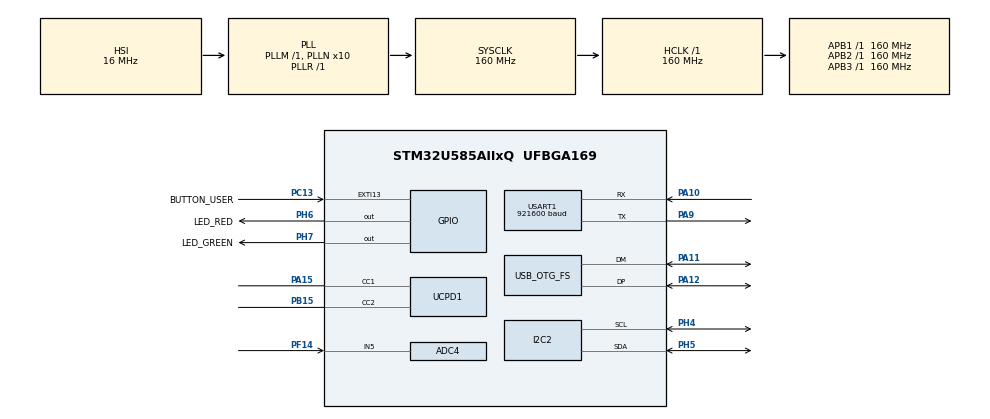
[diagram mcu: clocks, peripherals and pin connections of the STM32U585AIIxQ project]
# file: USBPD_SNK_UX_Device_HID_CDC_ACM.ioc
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ADC4.Channel-1\#ChannelRegularConversion=ADC_CHANNEL_5
ADC4.ClockPrescaler=ADC_CLOCK_ASYNC_DIV4
ADC4.ContinuousConvMode=ENABLE
ADC4.NbrOfConversion=1
ADC4.NbrOfConversionFlag=1
ADC4.OffsetNumber-1\#ChannelRegularConversion=ADC_OFFSET_NONE
ADC4.Overrun=ADC_OVR_DATA_OVERWRITTEN
ADC4.Rank-1\#ChannelRegularConversion=1
ADC4.RankArg-1\#ChannelRegularConversion=ADC4_REGULAR_RANK_1
ADC4.SamplingTime-1\#ChannelRegularConversion=ADC4_SAMPLINGTIME_COMMON_1
ADC4.SamplingTimeCommon1=ADC4_SAMPLETIME_814CYCLES_5
ADC4.SelectedChannel=ADC_CHANNEL_5
ADC4.Sequencer=FULLY_CONFIGURABLE
ADC4.TriggerFrequencyMode=ADC_TRIGGER_FREQ_HIGH
CORTEX_M33_NS.userName=CORTEX_M33
GPDMA1.DESTINC_GPDMACH5=DMA_DINC_INCREMENTED
GPDMA1.DIRECTION_GPDMACH3=DMA_MEMORY_TO_PERIPH
GPDMA1.DIRECTION_GPDMACH6=DMA_MEMORY_TO_PERIPH
GPDMA1.IPHANDLE_GPDMACH3-SIMPLEREQUEST_GPDMACH3=__NULL
GPDMA1.IPHANDLE_GPDMACH5-SIMPLEREQUEST_GPDMACH5=__NULL
GPDMA1.IPHANDLE_GPDMACH6-SIMPLEREQUEST_GPDMACH6=__NULL
GPDMA1.REQUEST_GPDMACH3=GPDMA1_REQUEST_UCPD1_TX
GPDMA1.REQUEST_GPDMACH5=GPDMA1_REQUEST_UCPD1_RX
GPDMA1.REQUEST_GPDMACH6=GPDMA1_REQUEST_USART1_TX
GPDMA1.SRCINC_GPDMACH3=DMA_SINC_INCREMENTED
GPDMA1.SRCINC_GPDMACH6=DMA_SINC_INCREMENTED
I2C2.Timing=0x30909DEC
Mcu.Family=STM32U5
Mcu.Name=STM32U585AIIxQ
Mcu.Package=UFBGA169
NVIC.EXTI13_IRQn=true\:7\:0\:true\:false\:true\:false\:true\:true\:true
NVIC.GPDMA1_Channel3_IRQn=true\:0\:0\:false\:false\:true\:true\:false\:true\:true
NVIC.GPDMA1_Channel5_IRQn=true\:0\:0\:false\:false\:true\:true\:false\:true\:true
NVIC.GPDMA1_Channel6_IRQn=true\:0\:0\:false\:false\:true\:true\:false\:true\:true
NVIC.OTG_FS_IRQn=true\:6\:0\:true\:false\:true\:false\:true\:true\:true
NVIC.PriorityGroup=NVIC_PRIORITYGROUP_4
NVIC.TIM6_IRQn=true\:15\:0\:false\:false\:true\:false\:false\:true\:true
NVIC.TimeBase=TIM6_IRQn
NVIC.TimeBaseIP=TIM6
NVIC.UCPD1_IRQn=true\:5\:0\:true\:false\:true\:false\:true\:false\:true
NVIC.USART1_IRQn=true\:4\:0\:true\:false\:true\:false\:true\:true\:true
PA10.GPIO_PuPd=GPIO_PULLUP
PA10.GPIO_Speed=GPIO_SPEED_FREQ_HIGH
PA10.Mode=Asynchronous
PA10.Signal=USART1_RX
PA11.GPIO_Speed=GPIO_SPEED_FREQ_VERY_HIGH
PA11.Mode=Device_Only
PA11.Signal=USB_OTG_FS_DM
PA12.GPIO_Speed=GPIO_SPEED_FREQ_VERY_HIGH
PA12.Mode=Device_Only
PA12.Signal=USB_OTG_FS_DP
PA15\ (JTDI).Mode=Sink_AllSignals
PA15\ (JTDI).Signal=UCPD1_CC1
PA9.GPIO_PuPd=GPIO_PULLUP
PA9.GPIO_Speed=GPIO_SPEED_FREQ_HIGH
PA9.Mode=Asynchronous
PA9.Signal=USART1_TX
PB15.Mode=Sink_AllSignals
PB15.Signal=UCPD1_CC2
PC13.GPIO_Label=BUTTON_USER
PC13.Signal=GPXTI13
PF14.Mode=IN5
PF14.Signal=ADC4_IN5
PH4.Mode=I2C
PH4.Signal=I2C2_SCL
PH5.Mode=I2C
PH5.Signal=I2C2_SDA
PH6.GPIO_Label=LED_RED
PH6.PinState=GPIO_PIN_SET
PH6.Signal=GPIO_Output
PH7.GPIO_Label=LED_GREEN
PH7.PinState=GPIO_PIN_SET
PH7.Signal=GPIO_Output
PWR.PowerMode=PWR_SMPS_SUPPLY
ProjectManager.HeapSize=0x1000
ProjectManager.StackSize=0x1000
ProjectManager.TargetToolchain=EWARM V8.50
RCC.ADCFreq_Value=16000000
RCC.AHBFreq_Value=160000000
RCC.APB1Freq_Value=160000000
RCC.APB1TimFreq_Value=160000000
RCC.APB2Freq_Value=160000000
RCC.APB2TimFreq_Value=160000000
RCC.APB3Freq_Value=160000000
RCC.CortexFreq_Value=160000000
RCC.DACCLockSelectionVirtual=RCC_DAC1CLKSOURCE_LSI
RCC.EPOD_VALUE=16000000
RCC.FLatency=FLASH_LATENCY_4
RCC.HCLKFreq_Value=160000000
RCC.HSE_VALUE=16000000
RCC.HSI48_VALUE=48000000
RCC.HSI_VALUE=16000000
RCC.LSE_VALUE=32768
RCC.LSIDIV_VALUE=32000
RCC.MSI_VALUE=4000000
RCC.PLL1R=1
RCC.PLLN=10
RCC.PLLSourceVirtual=RCC_PLLSOURCE_HSI
RCC.PWR_Regulator_Voltage_Scale=PWR_REGULATOR_VOLTAGE_SCALE1
RCC.SYSCLKFreq_VALUE=160000000
RCC.SYSCLKSource=RCC_SYSCLKSOURCE_PLLCLK
RCC.USBFreq_Value=48000000
RCC.VCOOutputFreq_Value=160000000
THREADX.AZRTOS_APP_MEM_ALLOCATION_METHOD=1
THREADX.TX_TIMER_TICKS_PER_SECOND=1000
USART1.BaudRate=921600
USART1.VirtualMode-Asynchronous=VM_ASYNC
USBPD.PE_DR_Swap_To_DFP_P0=USBPD_FALSE
USBPD.PE_DR_Swap_To_UFP_P0=USBPD_FALSE
USBPD.PE_SpecRevision_P0=USBPD_SPECIFICATION_REV3
USBPD.PORT0_SINK_PDO1=0x04019096
USBPD.USBPD_DEVICE_APP_MEM_POOL_SIZE=5000
USBPD.USBPD_PDO_FIXED_USBCOMM_P0=USBPD_PDO_FIXED_USBCOMM_SUPPORTED
USBPD.USBPD_PORT0_PDO_SNK_FIXED_SET_OP_CURRENT_0=1500
USBX.BSP.number=1
USBX.Core_System=1
USBX.MAX_POWER_IN_MILLI_AMPER=0
USBX.REG_USBX_DEVICE_CON_CK=0
USBX.USBD_CDCACM_EPINCMD_ADDR=2
USBX.USBD_CDCACM_EPIN_ADDR=1
USBX.USBD_HID_MOUSE_EPIN_ADDR=3
USBX.USBD_PID=22288
USBX.USBD_PRODUCT_STRING=STM32 HID CDC_ACM
USBX.USBD_SERIAL_NUMBER=COMP001
USBX.USBX_SYS_SIZE=10 * 1024
USBX.UX_APP_MEM_POOL_SIZE=15360
USBX.UX_DEVICE_CDC_ACM=1
USBX.UX_DEVICE_CLASS_CDC_ACM_TRANSMISSION_DISABLE=1
USBX.UX_DEVICE_CLASS_CDC_ACM_WRITE_AUTO_ZLP=1
USBX.UX_DEVICE_HID_CORE=1
USBX.UX_DEVICE_HID_MOUSE=1
USBX.UX_Device_Controller=1
USBX.UX_Device_CoreStack=1
USBX.UX_MAX_SLAVE_CLASS_DRIVER=2
USBX.UX_SLAVE_REQUEST_DATA_MAX_LENGTH=512
USBX0.BSP.STBoard=false
USBX0.BSP.api=Unknown
USBX0.BSP.instance=USB_OTG_FS
USBX0.BSP.ip=USB_OTG_FS
USBX0.BSP.mode=Device_Only
USBX0.BSP.name=USBDevice
USBX0.BSP.solution=USB_OTG_FS
USB_OTG_FS.VirtualMode=Device_Only
VP_GPDMA1_VS_GPDMACH3.Mode=SIMPLEREQUEST_GPDMACH3
VP_GPDMA1_VS_GPDMACH5.Mode=SIMPLEREQUEST_GPDMACH5
VP_GPDMA1_VS_GPDMACH6.Mode=SIMPLEREQUEST_GPDMACH6
VP_ICACHE_VS_ICACHE.Mode=DirectMappedCache
VP_LPBAMQUEUE_VS_QUEUE.Mode=QUEUEMODE
VP_LPBAM_VS_SIG1.Mode=SmartRun
VP_LPBAM_VS_SIG4.Mode=LPDMA1
VP_PWR_VS_DBSignals.Mode=DisableDeadBatterySignals
VP_PWR_VS_LPOM.Mode=PowerOptimisation
VP_PWR_VS_SECSignals.Mode=Security/Privilege
VP_RCC_USB.Mode=CRS SYNC Source USB
VP_SYS_VS_tim6.Mode=TIM6
VP_THREADX_VS_RTOSJjThreadXJjCoreJjDefault.Mode=Core_Default
VP_USBPD_VS_PD3FULL.Mode=PD3_Full_Stack
VP_USBPD_VS_USBPD1.Mode=USBPD_P0
VP_USBPD_VS_usbpd_tim2.Mode=TIM2
VP_USBPD_VS_usbpd_usb_cohabitation.Mode=Enable USB Support
VP_USBX_Core_System.Mode=Core_System
VP_USBX_UX\ Device\ CDC\ ACM\ Class_FS.Mode=UX_Device_class_CDC_ACM_FS
VP_USBX_UX\ Device\ Controller_FS.Mode=UX_Device_Controller_FS
VP_USBX_UX\ Device\ CoreStack_FS.Mode=UX_Device_CoreStack_FS
VP_USBX_UX\ Device\ HID_CORE_FS.Mode=UX_Device_class_HID_CORE_FS
VP_USBX_UX\ Device\ HID_MOUSE_FS.Mode=UX_Device_class_HID_MOUSE_FS
board=custom

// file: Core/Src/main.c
/* USER CODE BEGIN Header */
/**
  ******************************************************************************
  * @file           : main.c
  * @brief          : Main program body
  ******************************************************************************
  * @attention
  *
  * Copyright (c) 2021 STMicroelectronics.
  * All rights reserved.
  *
  * This software is licensed under terms that can be found in the LICENSE file
  * in the root directory of this software component.
  * If no LICENSE file comes with this software, it is provided AS-IS.
  *
  ******************************************************************************
  */
/* USER CODE END Header */
#include "app_threadx.h"
#include "main.h"
#include "usbpd.h"

/* USER CODE BEGIN Includes */
#include "b_u585i_iot02a.h"
/* USER CODE END Includes */

ADC_HandleTypeDef hadc4;

I2C_HandleTypeDef hi2c2;

UART_HandleTypeDef huart1;
DMA_HandleTypeDef handle_GPDMA1_Channel6;

PCD_HandleTypeDef hpcd_USB_OTG_FS;

void SystemClock_Config(void);
static void SystemPower_Config(void);
static void MX_GPIO_Init(void);
static void MX_GPDMA1_Init(void);
static void MX_UCPD1_Init(void);
static void MX_ICACHE_Init(void);
static void MX_ADC4_Init(void);
static void MX_I2C2_Init(void);

int main(void)
{

  /* MCU Configuration--------------------------------------------------------*/

  /* Reset of all peripherals, Initializes the Flash interface and the Systick. */
  HAL_Init();

  /* Configure the System Power */
  SystemPower_Config();

  /* Configure the system clock */
  SystemClock_Config();

  /* Initialize all configured peripherals */
  MX_GPIO_Init();
  MX_GPDMA1_Init();
  MX_UCPD1_Init();
  MX_ICACHE_Init();
  MX_USART1_UART_Init();
  MX_ADC4_Init();
  MX_I2C2_Init();
  /* Call PreOsInit function */
  USBPD_PreInitOs();

  MX_ThreadX_Init();

  /* We should never get here as control is now taken by the scheduler */

  /* Infinite loop */
  while (1)
  {

  }
}

void SystemClock_Config(void)
{
  RCC_OscInitTypeDef RCC_OscInitStruct = {0};
  RCC_ClkInitTypeDef RCC_ClkInitStruct = {0};
  RCC_CRSInitTypeDef RCC_CRSInitStruct = {0};

  /** Configure the main internal regulator output voltage
  */
  if (HAL_PWREx_ControlVoltageScaling(PWR_REGULATOR_VOLTAGE_SCALE1) != HAL_OK)
  {
    Error_Handler();
  }

  /** Initializes the CPU, AHB and APB buses clocks
  */
  RCC_OscInitStruct.OscillatorType = RCC_OSCILLATORTYPE_HSI48|RCC_OSCILLATORTYPE_HSI;
  RCC_OscInitStruct.HSIState = RCC_HSI_ON;
  RCC_OscInitStruct.HSI48State = RCC_HSI48_ON;
  RCC_OscInitStruct.HSICalibrationValue = RCC_HSICALIBRATION_DEFAULT;
  RCC_OscInitStruct.PLL.PLLState = RCC_PLL_ON;
  RCC_OscInitStruct.PLL.PLLSource = RCC_PLLSOURCE_HSI;
  RCC_OscInitStruct.PLL.PLLMBOOST = RCC_PLLMBOOST_DIV1;
  RCC_OscInitStruct.PLL.PLLM = 1;
  RCC_OscInitStruct.PLL.PLLN = 10;
  RCC_OscInitStruct.PLL.PLLP = 2;
  RCC_OscInitStruct.PLL.PLLQ = 2;
  RCC_OscInitStruct.PLL.PLLR = 1;
  RCC_OscInitStruct.PLL.PLLRGE = RCC_PLLVCIRANGE_1;
  RCC_OscInitStruct.PLL.PLLFRACN = 0;
  if (HAL_RCC_OscConfig(&RCC_OscInitStruct) != HAL_OK)
  {
    Error_Handler();
  }

  /** Initializes the CPU, AHB and APB buses clocks
  */
  RCC_ClkInitStruct.ClockType = RCC_CLOCKTYPE_HCLK|RCC_CLOCKTYPE_SYSCLK
                              |RCC_CLOCKTYPE_PCLK1|RCC_CLOCKTYPE_PCLK2
                              |RCC_CLOCKTYPE_PCLK3;
  RCC_ClkInitStruct.SYSCLKSource = RCC_SYSCLKSOURCE_PLLCLK;
  RCC_ClkInitStruct.AHBCLKDivider = RCC_SYSCLK_DIV1;
  RCC_ClkInitStruct.APB1CLKDivider = RCC_HCLK_DIV1;
  RCC_ClkInitStruct.APB2CLKDivider = RCC_HCLK_DIV1;
  RCC_ClkInitStruct.APB3CLKDivider = RCC_HCLK_DIV1;

  if (HAL_RCC_ClockConfig(&RCC_ClkInitStruct, FLASH_LATENCY_4) != HAL_OK)
  {
    Error_Handler();
  }

  /** Enable the SYSCFG APB clock
  */
  __HAL_RCC_CRS_CLK_ENABLE();

  /** Configures CRS
  */
  RCC_CRSInitStruct.Prescaler = RCC_CRS_SYNC_DIV1;
  RCC_CRSInitStruct.Source = RCC_CRS_SYNC_SOURCE_USB;
  RCC_CRSInitStruct.Polarity = RCC_CRS_SYNC_POLARITY_RISING;
  RCC_CRSInitStruct.ReloadValue = __HAL_RCC_CRS_RELOADVALUE_CALCULATE(48000000,1000);
  RCC_CRSInitStruct.ErrorLimitValue = 34;
  RCC_CRSInitStruct.HSI48CalibrationValue = 32;

  HAL_RCCEx_CRSConfig(&RCC_CRSInitStruct);
}

/**
  * @brief Power Configuration
  * @retval None
  */
static void SystemPower_Config(void)
{

  /*
   * Switch to SMPS regulator instead of LDO
   */
  if (HAL_PWREx_ConfigSupply(PWR_SMPS_SUPPLY) != HAL_OK)
  {
    Error_Handler();
  }
}

static void MX_ADC4_Init(void)
{

  ADC_ChannelConfTypeDef sConfig = {0};

  /* USER CODE BEGIN ADC4_Init 1 */
  hadc4.Init.LowPowerAutoPowerOff = ADC_LOW_POWER_NONE;
  hadc4.Init.SamplingTimeCommon1 = ADC_SAMPLETIME_391CYCLES_5;
  hadc4.Init.SamplingTimeCommon2 = ADC_SAMPLETIME_391CYCLES_5;

  /* USER CODE END ADC4_Init 1 */

  /** Common config
  */
  hadc4.Instance = ADC4;
  hadc4.Init.ClockPrescaler = ADC_CLOCK_ASYNC_DIV4;
  hadc4.Init.Resolution = ADC_RESOLUTION_12B;
  hadc4.Init.DataAlign = ADC_DATAALIGN_RIGHT;
  hadc4.Init.ScanConvMode = ADC4_SCAN_DISABLE;
  hadc4.Init.EOCSelection = ADC_EOC_SINGLE_CONV;
  hadc4.Init.LowPowerAutoPowerOff = ADC_LOW_POWER_NONE;
  hadc4.Init.LowPowerAutoWait = DISABLE;
  hadc4.Init.ContinuousConvMode = ENABLE;
  hadc4.Init.NbrOfConversion = 1;
  hadc4.Init.ExternalTrigConv = ADC_SOFTWARE_START;
  hadc4.Init.ExternalTrigConvEdge = ADC_EXTERNALTRIGCONVEDGE_NONE;
  hadc4.Init.DMAContinuousRequests = DISABLE;
  hadc4.Init.TriggerFrequencyMode = ADC_TRIGGER_FREQ_HIGH;
  hadc4.Init.Overrun = ADC_OVR_DATA_OVERWRITTEN;
  hadc4.Init.SamplingTimeCommon1 = ADC4_SAMPLETIME_814CYCLES_5;
  hadc4.Init.SamplingTimeCommon2 = ADC4_SAMPLETIME_1CYCLE_5;
  hadc4.Init.OversamplingMode = DISABLE;
  if (HAL_ADC_Init(&hadc4) != HAL_OK)
  {
    Error_Handler();
  }

  /** Configure Regular Channel
  */
  sConfig.Channel = ADC_CHANNEL_5;
  sConfig.Rank = ADC4_REGULAR_RANK_1;
  sConfig.SamplingTime = ADC4_SAMPLINGTIME_COMMON_1;
  sConfig.OffsetNumber = ADC_OFFSET_NONE;
  sConfig.Offset = 0;
  if (HAL_ADC_ConfigChannel(&hadc4, &sConfig) != HAL_OK)
  {
    Error_Handler();
  }

}

static void MX_GPDMA1_Init(void)
{

  /* Peripheral clock enable */
  __HAL_RCC_GPDMA1_CLK_ENABLE();

  /* GPDMA1 interrupt Init */
    HAL_NVIC_SetPriority(GPDMA1_Channel3_IRQn, 0, 0);
    HAL_NVIC_EnableIRQ(GPDMA1_Channel3_IRQn);
    HAL_NVIC_SetPriority(GPDMA1_Channel5_IRQn, 0, 0);
    HAL_NVIC_EnableIRQ(GPDMA1_Channel5_IRQn);
    HAL_NVIC_SetPriority(GPDMA1_Channel6_IRQn, 0, 0);
    HAL_NVIC_EnableIRQ(GPDMA1_Channel6_IRQn);

}

static void MX_I2C2_Init(void)
{

  hi2c2.Instance = I2C2;
  hi2c2.Init.Timing = 0x30909DEC;
  hi2c2.Init.OwnAddress1 = 0;
  hi2c2.Init.AddressingMode = I2C_ADDRESSINGMODE_7BIT;
  hi2c2.Init.DualAddressMode = I2C_DUALADDRESS_DISABLE;
  hi2c2.Init.OwnAddress2 = 0;
  hi2c2.Init.OwnAddress2Masks = I2C_OA2_NOMASK;
  hi2c2.Init.GeneralCallMode = I2C_GENERALCALL_DISABLE;
  hi2c2.Init.NoStretchMode = I2C_NOSTRETCH_DISABLE;
  if (HAL_I2C_Init(&hi2c2) != HAL_OK)
  {
    Error_Handler();
  }

  /** Configure Analogue filter
  */
  if (HAL_I2CEx_ConfigAnalogFilter(&hi2c2, I2C_ANALOGFILTER_ENABLE) != HAL_OK)
  {
    Error_Handler();
  }

  /** Configure Digital filter
  */
  if (HAL_I2CEx_ConfigDigitalFilter(&hi2c2, 0) != HAL_OK)
  {
    Error_Handler();
  }

}

static void MX_ICACHE_Init(void)
{

  /** Enable instruction cache in 1-way (direct mapped cache)
  */
  if (HAL_ICACHE_ConfigAssociativityMode(ICACHE_1WAY) != HAL_OK)
  {
    Error_Handler();
  }
  if (HAL_ICACHE_Enable() != HAL_OK)
  {
    Error_Handler();
  }

}

static void MX_UCPD1_Init(void)
{

  LL_GPIO_InitTypeDef GPIO_InitStruct = {0};
  LL_DMA_InitTypeDef DMA_InitStruct = {0};

  /* Peripheral clock enable */
  LL_APB1_GRP2_EnableClock(LL_APB1_GRP2_PERIPH_UCPD1);

  LL_AHB2_GRP1_EnableClock(LL_AHB2_GRP1_PERIPH_GPIOA);
  LL_AHB2_GRP1_EnableClock(LL_AHB2_GRP1_PERIPH_GPIOB);
  /**UCPD1 GPIO Configuration
  PA15 (JTDI)   ------> UCPD1_CC1
  PB15   ------> UCPD1_CC2
  */
  GPIO_InitStruct.Pin = LL_GPIO_PIN_15;
  GPIO_InitStruct.Mode = LL_GPIO_MODE_ANALOG;
  GPIO_InitStruct.Pull = LL_GPIO_PULL_NO;
  LL_GPIO_Init(GPIOA, &GPIO_InitStruct);

  GPIO_InitStruct.Pin = LL_GPIO_PIN_15;
  GPIO_InitStruct.Mode = LL_GPIO_MODE_ANALOG;
  GPIO_InitStruct.Pull = LL_GPIO_PULL_NO;
  LL_GPIO_Init(GPIOB, &GPIO_InitStruct);

  /* UCPD1 DMA Init */

  /* GPDMA1_REQUEST_UCPD1_RX Init */
  DMA_InitStruct.SrcAddress = 0x00000000U;
  DMA_InitStruct.DestAddress = 0x00000000U;
  DMA_InitStruct.Direction = LL_DMA_DIRECTION_PERIPH_TO_MEMORY;
  DMA_InitStruct.BlkHWRequest = LL_DMA_HWREQUEST_SINGLEBURST;
  DMA_InitStruct.DataAlignment = LL_DMA_DATA_ALIGN_ZEROPADD;
  DMA_InitStruct.SrcBurstLength = 1;
  DMA_InitStruct.DestBurstLength = 1;
  DMA_InitStruct.SrcDataWidth = LL_DMA_SRC_DATAWIDTH_BYTE;
  DMA_InitStruct.DestDataWidth = LL_DMA_DEST_DATAWIDTH_BYTE;
  DMA_InitStruct.SrcIncMode = LL_DMA_SRC_FIXED;
  DMA_InitStruct.DestIncMode = LL_DMA_DEST_INCREMENT;
  DMA_InitStruct.Priority = LL_DMA_LOW_PRIORITY_LOW_WEIGHT;
  DMA_InitStruct.BlkDataLength = 0x00000000U;
  DMA_InitStruct.TriggerMode = LL_DMA_TRIGM_BLK_TRANSFER;
  DMA_InitStruct.TriggerPolarity = LL_DMA_TRIG_POLARITY_MASKED;
  DMA_InitStruct.TriggerSelection = 0x00000000U;
  DMA_InitStruct.Request = LL_GPDMA1_REQUEST_UCPD1_RX;
  DMA_InitStruct.TransferEventMode = LL_DMA_TCEM_BLK_TRANSFER;
  DMA_InitStruct.SrcAllocatedPort = LL_DMA_SRC_ALLOCATED_PORT0;
  DMA_InitStruct.DestAllocatedPort = LL_DMA_DEST_ALLOCATED_PORT0;
  DMA_InitStruct.LinkAllocatedPort = LL_DMA_LINK_ALLOCATED_PORT1;
  DMA_InitStruct.LinkStepMode = LL_DMA_LSM_FULL_EXECUTION;
  DMA_InitStruct.LinkedListBaseAddr = 0x00000000U;
  DMA_InitStruct.LinkedListAddrOffset = 0x00000000U;
  LL_DMA_Init(GPDMA1, LL_DMA_CHANNEL_5, &DMA_InitStruct);

  /* GPDMA1_REQUEST_UCPD1_TX Init */
  DMA_InitStruct.SrcAddress = 0x00000000U;
  DMA_InitStruct.DestAddress = 0x00000000U;
  DMA_InitStruct.Direction = LL_DMA_DIRECTION_MEMORY_TO_PERIPH;
  DMA_InitStruct.BlkHWRequest = LL_DMA_HWREQUEST_SINGLEBURST;
  DMA_InitStruct.DataAlignment = LL_DMA_DATA_ALIGN_ZEROPADD;
  DMA_InitStruct.SrcBurstLength = 1;
  DMA_InitStruct.DestBurstLength = 1;
  DMA_InitStruct.SrcDataWidth = LL_DMA_SRC_DATAWIDTH_BYTE;
  DMA_InitStruct.DestDataWidth = LL_DMA_DEST_DATAWIDTH_BYTE;
  DMA_InitStruct.SrcIncMode = LL_DMA_SRC_INCREMENT;
  DMA_InitStruct.DestIncMode = LL_DMA_DEST_FIXED;
  DMA_InitStruct.Priority = LL_DMA_LOW_PRIORITY_LOW_WEIGHT;
  DMA_InitStruct.BlkDataLength = 0x00000000U;
  DMA_InitStruct.TriggerMode = LL_DMA_TRIGM_BLK_TRANSFER;
  DMA_InitStruct.TriggerPolarity = LL_DMA_TRIG_POLARITY_MASKED;
  DMA_InitStruct.TriggerSelection = 0x00000000U;
  DMA_InitStruct.Request = LL_GPDMA1_REQUEST_UCPD1_TX;
  DMA_InitStruct.TransferEventMode = LL_DMA_TCEM_BLK_TRANSFER;
  DMA_InitStruct.SrcAllocatedPort = LL_DMA_SRC_ALLOCATED_PORT0;
  DMA_InitStruct.DestAllocatedPort = LL_DMA_DEST_ALLOCATED_PORT0;
  DMA_InitStruct.LinkAllocatedPort = LL_DMA_LINK_ALLOCATED_PORT1;
  DMA_InitStruct.LinkStepMode = LL_DMA_LSM_FULL_EXECUTION;
  DMA_InitStruct.LinkedListBaseAddr = 0x00000000U;
  DMA_InitStruct.LinkedListAddrOffset = 0x00000000U;
  LL_DMA_Init(GPDMA1, LL_DMA_CHANNEL_3, &DMA_InitStruct);

  /* UCPD1 interrupt Init */
  NVIC_SetPriority(UCPD1_IRQn, NVIC_EncodePriority(NVIC_GetPriorityGrouping(),5, 0));
  NVIC_EnableIRQ(UCPD1_IRQn);

}

void MX_USART1_UART_Init(void)
{

  huart1.Instance = USART1;
  huart1.Init.BaudRate = 921600;
  huart1.Init.WordLength = UART_WORDLENGTH_8B;
  huart1.Init.StopBits = UART_STOPBITS_1;
  huart1.Init.Parity = UART_PARITY_NONE;
  huart1.Init.Mode = UART_MODE_TX_RX;
  huart1.Init.HwFlowCtl = UART_HWCONTROL_NONE;
  huart1.Init.OverSampling = UART_OVERSAMPLING_16;
  huart1.Init.OneBitSampling = UART_ONE_BIT_SAMPLE_DISABLE;
  huart1.Init.ClockPrescaler = UART_PRESCALER_DIV1;
  huart1.AdvancedInit.AdvFeatureInit = UART_ADVFEATURE_NO_INIT;
  if (HAL_UART_Init(&huart1) != HAL_OK)
  {
    Error_Handler();
  }
  if (HAL_UARTEx_SetTxFifoThreshold(&huart1, UART_TXFIFO_THRESHOLD_1_8) != HAL_OK)
  {
    Error_Handler();
  }
  if (HAL_UARTEx_SetRxFifoThreshold(&huart1, UART_RXFIFO_THRESHOLD_1_8) != HAL_OK)
  {
    Error_Handler();
  }
  if (HAL_UARTEx_DisableFifoMode(&huart1) != HAL_OK)
  {
    Error_Handler();
  }

}

void MX_USB_OTG_FS_PCD_Init(void)
{

  hpcd_USB_OTG_FS.Instance = USB_OTG_FS;
  hpcd_USB_OTG_FS.Init.dev_endpoints = 6;
  hpcd_USB_OTG_FS.Init.speed = PCD_SPEED_FULL;
  hpcd_USB_OTG_FS.Init.phy_itface = PCD_PHY_EMBEDDED;
  hpcd_USB_OTG_FS.Init.Sof_enable = DISABLE;
  hpcd_USB_OTG_FS.Init.low_power_enable = DISABLE;
  hpcd_USB_OTG_FS.Init.lpm_enable = DISABLE;
  hpcd_USB_OTG_FS.Init.battery_charging_enable = DISABLE;
  hpcd_USB_OTG_FS.Init.use_dedicated_ep1 = DISABLE;
  hpcd_USB_OTG_FS.Init.vbus_sensing_enable = DISABLE;
  hpcd_USB_OTG_FS.Init.dma_enable = DISABLE;
  if (HAL_PCD_Init(&hpcd_USB_OTG_FS) != HAL_OK)
  {
    Error_Handler();
  }
  /* USER CODE BEGIN USB_OTG_FS_Init 2 */
  HAL_PCDEx_SetRxFiFo(&hpcd_USB_OTG_FS, 0x80);
  HAL_PCDEx_SetTxFiFo(&hpcd_USB_OTG_FS, 0, USBD_MAX_EP0_SIZE / 4);
  HAL_PCDEx_SetTxFiFo(&hpcd_USB_OTG_FS, 1, USBD_CDCACM_EPIN_FS_MPS / 4);
  HAL_PCDEx_SetTxFiFo(&hpcd_USB_OTG_FS, 2, USBD_CDCACM_EPINCMD_FS_MPS /4);
  HAL_PCDEx_SetTxFiFo(&hpcd_USB_OTG_FS, 3, USBD_HID_MOUSE_EPIN_FS_MPS / 4);
  /* USER CODE END USB_OTG_FS_Init 2 */

}

static void MX_GPIO_Init(void)
{
  GPIO_InitTypeDef GPIO_InitStruct = {0};

  /* GPIO Ports Clock Enable */
  __HAL_RCC_GPIOA_CLK_ENABLE();
  __HAL_RCC_GPIOC_CLK_ENABLE();
  __HAL_RCC_GPIOH_CLK_ENABLE();
  __HAL_RCC_GPIOF_CLK_ENABLE();
  __HAL_RCC_GPIOB_CLK_ENABLE();

  /*Configure GPIO pin Output Level */
  HAL_GPIO_WritePin(GPIOH, LED_RED_Pin|LED_GREEN_Pin, GPIO_PIN_SET);

  /*Configure GPIO pin : BUTTON_USER_Pin */
  GPIO_InitStruct.Pin = BUTTON_USER_Pin;
  GPIO_InitStruct.Mode = GPIO_MODE_IT_RISING;
  GPIO_InitStruct.Pull = GPIO_NOPULL;
  HAL_GPIO_Init(BUTTON_USER_GPIO_Port, &GPIO_InitStruct);

  /*Configure GPIO pins : LED_RED_Pin LED_GREEN_Pin */
  GPIO_InitStruct.Pin = LED_RED_Pin|LED_GREEN_Pin;
  GPIO_InitStruct.Mode = GPIO_MODE_OUTPUT_PP;
  GPIO_InitStruct.Pull = GPIO_NOPULL;
  GPIO_InitStruct.Speed = GPIO_SPEED_FREQ_LOW;
  HAL_GPIO_Init(GPIOH, &GPIO_InitStruct);

  /* EXTI interrupt init*/
  HAL_NVIC_SetPriority(EXTI13_IRQn, 7, 0);
  HAL_NVIC_EnableIRQ(EXTI13_IRQn);

}

void HAL_TIM_PeriodElapsedCallback(TIM_HandleTypeDef *htim)
{
  if (htim->Instance == TIM6)
  {
    HAL_IncTick();
    USBPD_DPM_TimerCounter();
  }
}

void Error_Handler(void)
{
  /* USER CODE BEGIN Error_Handler_Debug */
  /* User can add his own implementation to report the HAL error return state */

  while (1)
  {
    HAL_GPIO_TogglePin(LED_RED_GPIO_Port, (uint16_t)LED_RED_Pin  );
    HAL_Delay(200);
  }
  /* USER CODE END Error_Handler_Debug */
}
